# STM32C593xx register map
File version: 1.0
Registers are 32-bit, read-write, reset 0x0 unless marked. A register's access mark holds for its fields unless they carry their own. Offsets are from the block's base; [hi:lo] are bit positions; {n}, {i} and the like mark numbered series; 'fields as' and 'values as' point back to an identical list.

## USB_DRD_PMA_BUFF — Universal Serial Bus PacketMemoryArea Buffer Descriptor Table
Base 0x40016400
0x00 TXBD — Transmission buffer address
0x04 RXBD — Reception buffer address

## LPDMA1 — DMA Controller (DMA)
Base 0x40020000
Same registers: LPDMA2 0x40021000
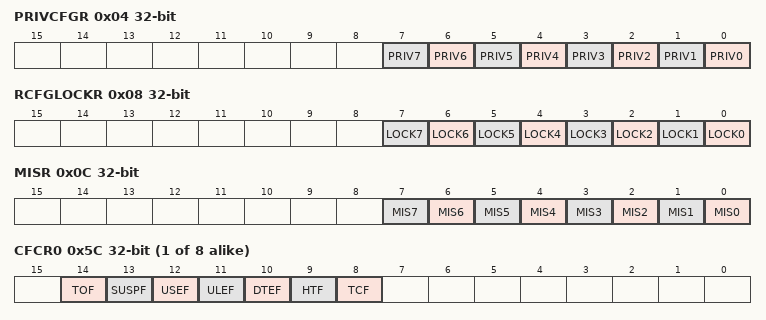
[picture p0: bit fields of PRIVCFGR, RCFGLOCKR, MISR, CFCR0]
0x04 PRIVCFGR — DMA privileged configuration register
  [n] PRIV{n} (n=0..7)
0x08 RCFGLOCKR — DMA configuration lock register
  [n] LOCK{n} (n=0..7)
0x0C MISR ro — DMA masked interrupt status register
  [n] MIS{n} (n=0..7)
{0x50+0x80*i} CLBAR{i} (i=0..7) — DMA channel x linked-list base address register
  [31:16] LBA
{0x5C+0x80*i} CFCR{i} (i=0..7) — DMA channel x flag clear register
  [14] TOF, [13] SUSPF, [12] USEF, [11] ULEF, [10] DTEF, [9] HTF, [8] TCF
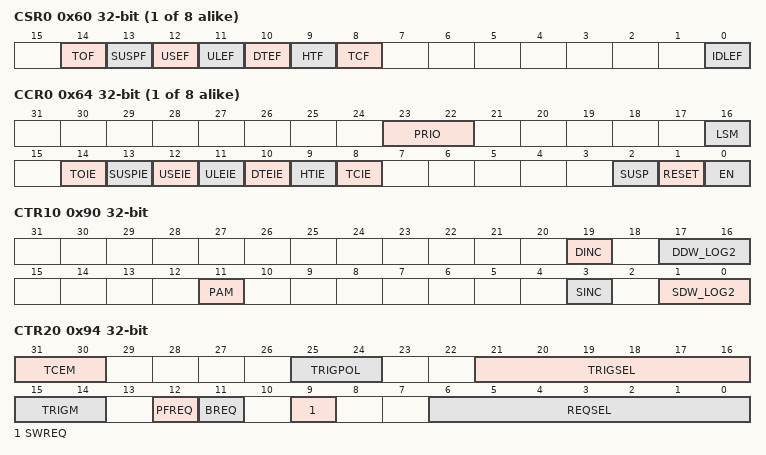
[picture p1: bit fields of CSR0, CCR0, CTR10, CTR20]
{0x60+0x80*i} CSR{i} ro (i=0..7) — DMA channel x flag status register
  [14] TOF — Trigger overrun flag
  [13] SUSPF — Completed suspension flag
  [12] USEF — User setting error flag
  [11] ULEF
  [10] DTEF — Data transfer error flag
  [9] HTF — Half transfer complete flag
  [8] TCF — Transfer complete flag
  [0] IDLEF — Idle flag
{0x64+0x80*i} CCR{i} (i=0..7) — DMA channel x control register
  [23:22] PRIO — Priority level
  [16] LSM — Link step mode
  [14] TOIE
  [13] SUSPIE
  [12] USEIE
  [11] ULEIE
  [10] DTEIE
  [9] HTIE
  [8] TCIE
  [2] SUSP — Channel suspend
  [1] RESET — Channel reset
  [0] EN — Channel enable
0x90 CTR10 — DMA channel x transfer register 1
  [19] DINC
  [17:16] DDW_LOG2
  [11] PAM — Padding / alignment mode
  [3] SINC — Source incrementing burst
  [1:0] SDW_LOG2
0x94 CTR20 — DMA channel x transfer register 2
  [31:30] TCEM
  [25:24] TRIGPOL
  [21:16] TRIGSEL
  [15:14] TRIGM — Trigger mode
  [12] PFREQ
  [11] BREQ — Block hardware request
  [9] SWREQ — Software request
  [6:0] REQSEL
0x98 CBR10 — DMA channel x block register 1
  [15:0] BNDT
{0x9C+0x80*i} CSAR{i} (i=0..7) — DMA channel x source address register
  [31:0] SA — Source Address
{0xA0+0x80*i} CDAR{i} (i=0..7) — DMA channel x destination address register
  [31:0] DA — Destination address
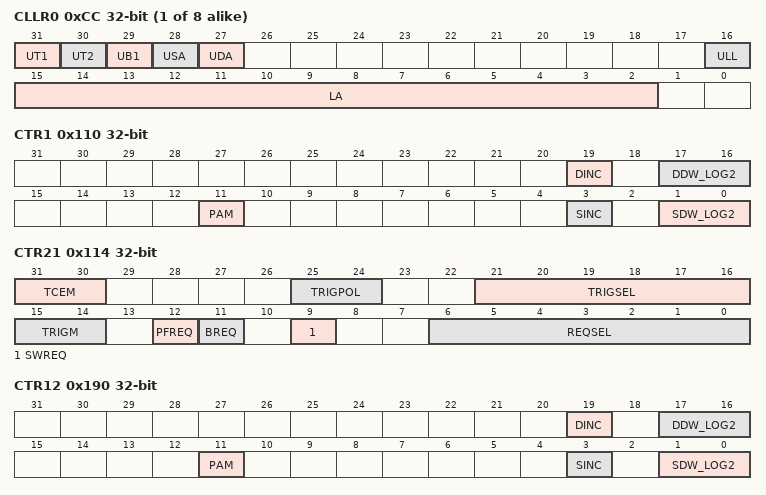
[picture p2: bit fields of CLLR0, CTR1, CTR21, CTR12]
{0xCC+0x80*i} CLLR{i} (i=0..7) — DMA channel x linked-list address register
  [31] UT1, [30] UT2, [29] UB1, [28] USA, [27] UDA, [16] ULL, [15:2] LA
0x110 CTR1 — DMA channel x transfer register 1
  fields as CTR10
0x114 CTR21 — DMA channel x transfer register 2
  fields as CTR20
0x118 CBR1 — DMA channel x block register 1
  [15:0] BNDT
0x190 CTR12 — DMA channel x transfer register 1
  fields as CTR10
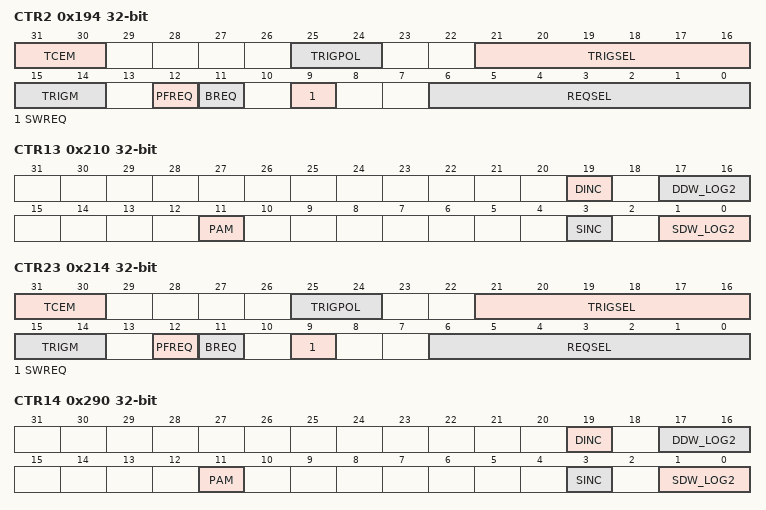
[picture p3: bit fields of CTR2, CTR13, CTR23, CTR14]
0x194 CTR2 — DMA channel x transfer register 2
  fields as CTR20
0x198 CBR12 — DMA channel x block register 1
  [15:0] BNDT
0x210 CTR13 — DMA channel x transfer register 1
  fields as CTR10
0x214 CTR23 — DMA channel x transfer register 2
  fields as CTR20
0x218 CBR13 — DMA channel x block register 1
  [15:0] BNDT
0x290 CTR14 — DMA channel x transfer register 1
  fields as CTR10
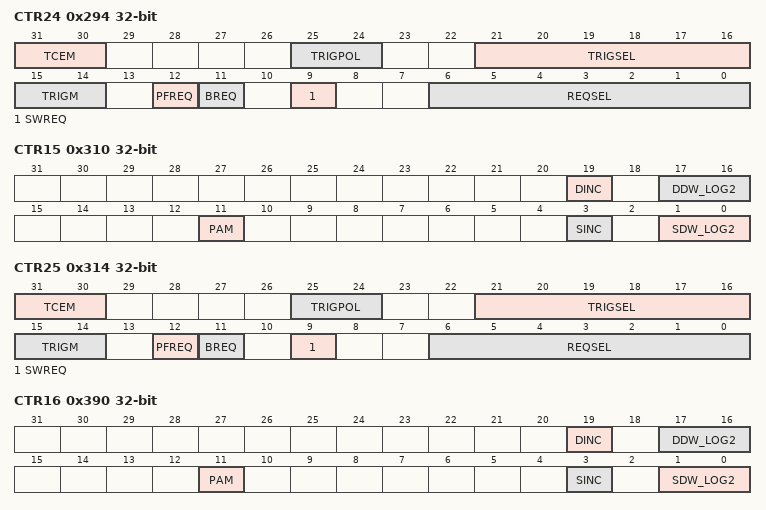
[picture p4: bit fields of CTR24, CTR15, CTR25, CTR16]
0x294 CTR24 — DMA channel x transfer register 2
  fields as CTR20
0x298 CBR14 — DMA channel x block register 1
  [15:0] BNDT
0x310 CTR15 — DMA channel x transfer register 1
  fields as CTR10
0x314 CTR25 — DMA channel x transfer register 2
  fields as CTR20
0x318 CBR15 — DMA channel x block register 1
  [15:0] BNDT
0x390 CTR16 — DMA channel x transfer register 1
  fields as CTR10
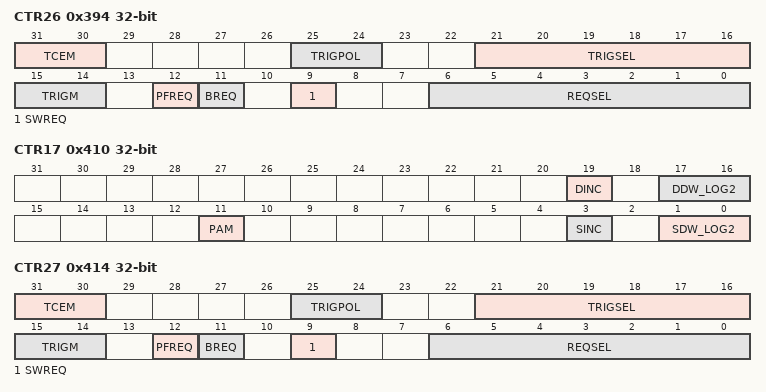
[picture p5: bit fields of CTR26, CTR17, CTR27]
0x394 CTR26 — DMA channel x transfer register 2
  fields as CTR20
0x398 CBR16 — DMA channel x block register 1
  [15:0] BNDT
0x410 CTR17 — DMA channel x transfer register 1
  fields as CTR10
0x414 CTR27 — DMA channel x transfer register 2
  fields as CTR20
0x418 CBR17 — DMA channel x block register 1
  [15:0] BNDT

## FLASH — FLASH Registers
Base 0x40022000
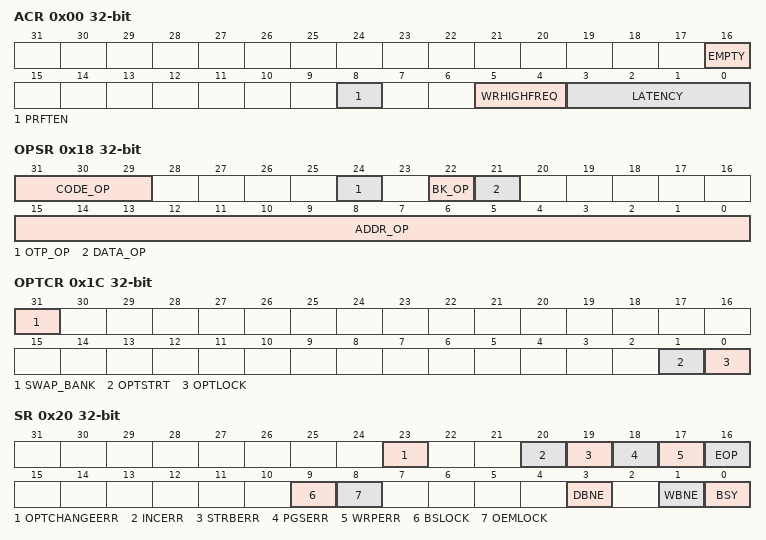
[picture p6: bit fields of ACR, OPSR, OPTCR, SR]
0x00 ACR — FLASH access control register
  [16] EMPTY
  [8] PRFTEN — Prefetch enable
  [5:4] WRHIGHFREQ — FLASH signal delay
  [3:0] LATENCY — Read latency
0x04 KEYR — FLASH key register
  [31:0] KEY
0x0C OPTKEYR — FLASH option key register
  [31:0] OPTKEY
0x18 OPSR ro — FLASH operation status register
  [31:29] CODE_OP, [24] OTP_OP, [22] BK_OP, [21] DATA_OP, [15:0] ADDR_OP
0x1C OPTCR — FLASH option control register
  [31] SWAP_BANK, [1] OPTSTRT, [0] OPTLOCK
0x20 SR ro — FLASH status register
  [23] OPTCHANGEERR
  [20] INCERR
  [19] STRBERR — strobe error flag
  [18] PGSERR
  [17] WRPERR
  [16] EOP
  [9] BSLOCK
  [8] OEMLOCK
  [3] DBNE
  [1] WBNE
  [0] BSY — busy flag
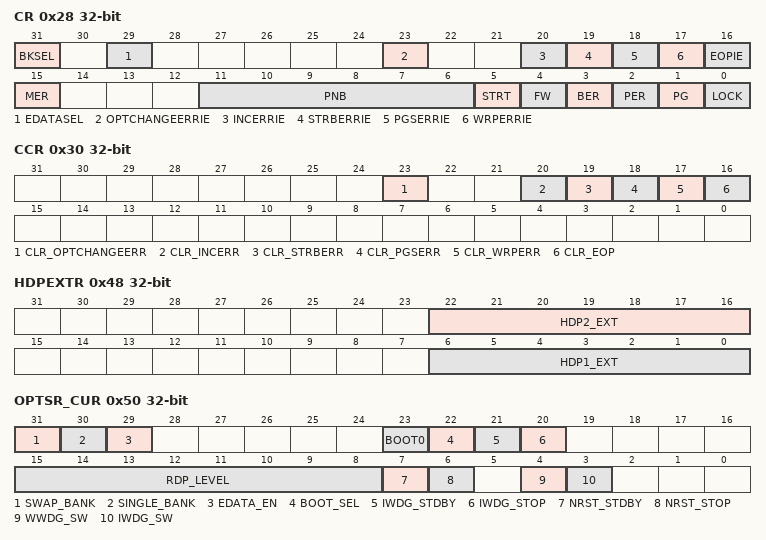
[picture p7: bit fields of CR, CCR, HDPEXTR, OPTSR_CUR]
0x28 CR — FLASH control register
  [31] BKSEL — Bank selector bit
  [29] EDATASEL
  [23] OPTCHANGEERRIE
  [20] INCERRIE
  [19] STRBERRIE
  [18] PGSERRIE
  [17] WRPERRIE
  [16] EOPIE
  [15] MER — Mass erase request
  [11:6] PNB
  [5] STRT
  [4] FW
  [3] BER — Bank erase request
  [2] PER — page erase request
  [1] PG
  [0] LOCK
0x30 CCR — FLASH clear control register
  [23] CLR_OPTCHANGEERR
  [20] CLR_INCERR
  [19] CLR_STRBERR
  [18] CLR_PGSERR
  [17] CLR_WRPERR
  [16] CLR_EOP — EOP flag clear bit
0x3C PRIVCFGR — FLASH privilege configuration register
  [1] PRIV — privilege attribute
0x48 HDPEXTR — FLASH HDP extension register
  [22:16] HDP2_EXT, [6:0] HDP1_EXT
0x50 OPTSR_CUR ro — FLASH option status register
  [31] SWAP_BANK
  [30] SINGLE_BANK
  [29] EDATA_EN
  [23] BOOT0 — Boot 0 option bit
  [22] BOOT_SEL
  [21] IWDG_STDBY
  [20] IWDG_STOP
  [15:8] RDP_LEVEL
  [7] NRST_STDBY
  [6] NRST_STOP
  [4] WWDG_SW
  [3] IWDG_SW
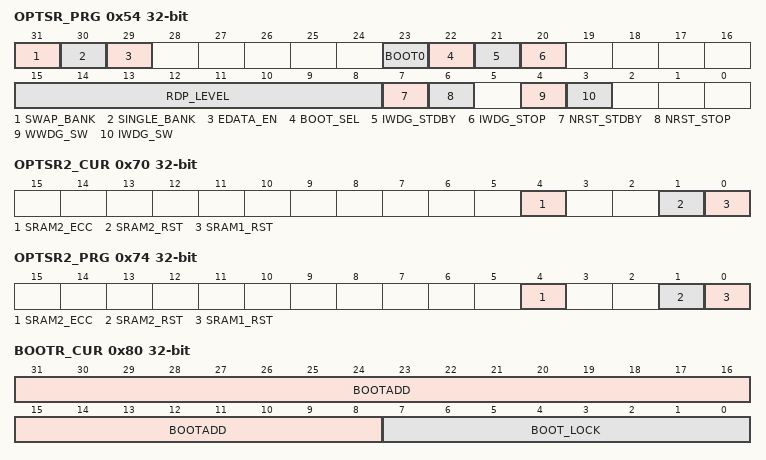
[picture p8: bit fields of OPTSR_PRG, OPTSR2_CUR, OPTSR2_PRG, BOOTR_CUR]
0x54 OPTSR_PRG — FLASH option status register
  fields as OPTSR_CUR
0x70 OPTSR2_CUR ro — FLASH option status register 2
  [4] SRAM2_ECC, [1] SRAM2_RST, [0] SRAM1_RST
0x74 OPTSR2_PRG — FLASH option status register 2
  [4] SRAM2_ECC, [1] SRAM2_RST, [0] SRAM1_RST
0x80 BOOTR_CUR ro — FLASH unique boot entry register
  [31:8] BOOTADD, [7:0] BOOT_LOCK
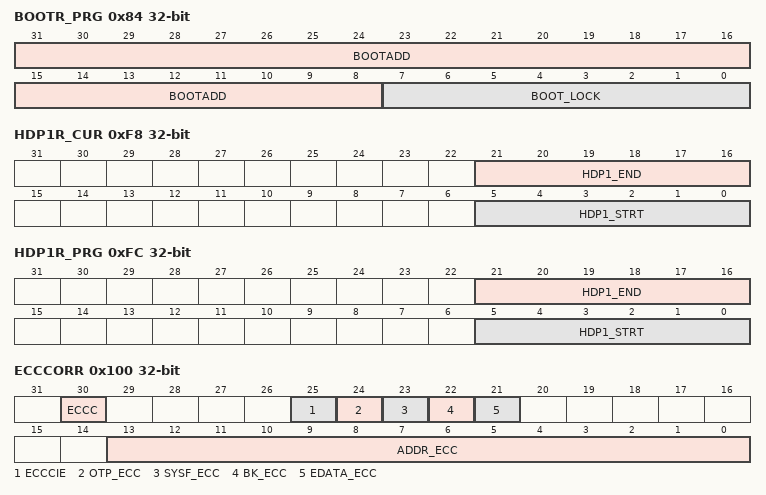
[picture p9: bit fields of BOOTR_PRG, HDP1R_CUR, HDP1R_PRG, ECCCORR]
0x84 BOOTR_PRG — FLASH unique boot entry address
  [31:8] BOOTADD, [7:0] BOOT_LOCK
0x90 OTPBLR_CUR ro — FLASH OTP block lock
  [23:0] LOCKBL — OTP block lock
0x94 OTPBLR_PRG — FLASH OTP block lock
  [23:0] LOCKBL — OTP block lock
0x98 BL_COM_CFG_CUR ro — FLASH Bootloader interface selection
  [31:0] BL_COM_CFG
0x9C BL_COM_CFG_PRG — FLASH Bootloader interface selection
  [31:0] BL_COM_CFG
{0x9C+8i} OEMKEYR{i}_PRG (i=1..4) — FLASH OEM Key register {i}
  [31:0] OEMKEY
0xC4 BSKEYR_PRG — FLASH Boundary Scan key register
  [31:0] BSKEY — Boundary Scan KEY
0xE8 WRP1R_CUR ro — FLASH write page protection for bank1
  [31:0] WRPSG1
0xEC WRP1R_PRG — FLASH write page protection for bank1
  [31:0] WRPSG1
0xF8 HDP1R_CUR ro — FLASH HDP bank1 register
  [21:16] HDP1_END, [5:0] HDP1_STRT
0xFC HDP1R_PRG — FLASH HDP bank1 register
  [21:16] HDP1_END, [5:0] HDP1_STRT
0x100 ECCCORR — FLASH ECC correction register
  [30] ECCC — ECC correction
  [25] ECCCIE
  [24] OTP_ECC — OTP ECC error bit
  [23] SYSF_ECC
  [22] BK_ECC
  [21] EDATA_ECC
  [13:0] ADDR_ECC — ECC error address
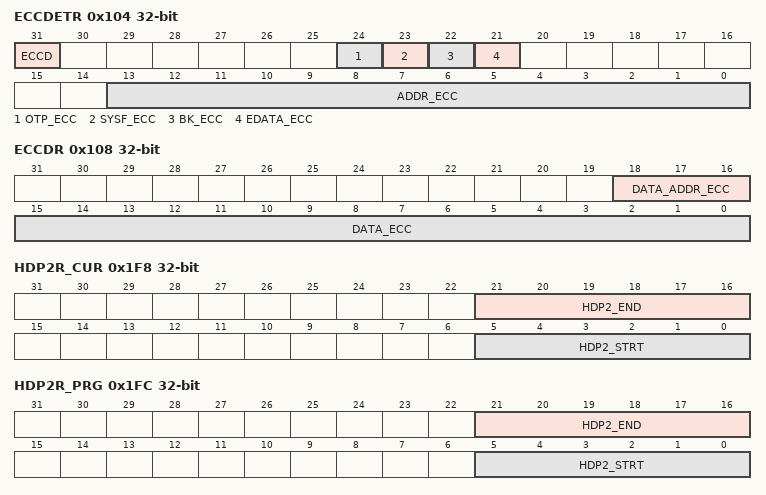
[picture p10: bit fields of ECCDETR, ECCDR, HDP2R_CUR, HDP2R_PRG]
0x104 ECCDETR — FLASH ECC detection register
  [31] ECCD
  [24] OTP_ECC — OTP ECC error bit
  [23] SYSF_ECC
  [22] BK_ECC
  [21] EDATA_ECC
  [13:0] ADDR_ECC — ECC error address
0x108 ECCDR ro — FLASH ECC data
  [18:16] DATA_ADDR_ECC
  [15:0] DATA_ECC — ECC error data
0x1E8 WRP2R_CUR ro — FLASH write page protection for bank2
  [31:0] WRPSG2
0x1EC WRP2R_PRG — FLASH write page protection for bank2
  [31:0] WRPSG2
0x1F8 HDP2R_CUR ro — FLASH HDP bank2 register
  [21:16] HDP2_END, [5:0] HDP2_STRT
0x1FC HDP2R_PRG — FLASH HDP bank2 register
  [21:16] HDP2_END, [5:0] HDP2_STRT
